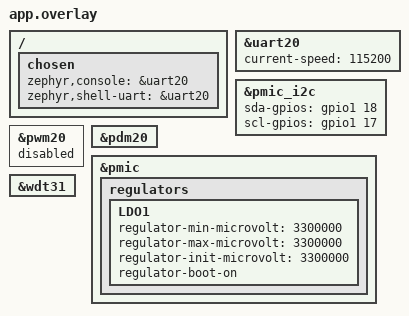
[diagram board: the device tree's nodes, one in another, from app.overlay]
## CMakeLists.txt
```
cmake_minimum_required(VERSION 3.20.0)

# SDK-specific devicetree fixups are applied on top of the auto-included
# app.overlay. They must be selected before find_package(Zephyr), because that
# call preprocesses the devicetree. The NCS and upstream board definitions do
# not expose the same nodes, so applying both overlays is not portable.
#
# A plain set() is correct and does not hide a caller's overlay: Zephyr reads
# this with zephyr_get(EXTRA_DTC_OVERLAY_FILE SYSBUILD LOCAL MERGE REVERSE),
# which merges every scope (sysbuild, CMake cache, environment, and this local
# variable) instead of letting the highest-precedence one win. A deployment
# overlay passed as -DEXTRA_DTC_OVERLAY_FILE=... therefore lands in the DTS list
# alongside the fixup below, with the fixup applied first.
get_filename_component(hive_zephyr_parent "$ENV{ZEPHYR_BASE}" DIRECTORY)
if(DEFINED NCS_DIR OR DEFINED ENV{NCS_DIR} OR
   EXISTS "${hive_zephyr_parent}/nrf/CMakeLists.txt")
  set(hive_sdk_overlay "ncs_fixups.overlay")
else()
  set(hive_sdk_overlay "upstream_fixups.overlay")
endif()
set(EXTRA_DTC_OVERLAY_FILE "${CMAKE_CURRENT_SOURCE_DIR}/${hive_sdk_overlay}")

find_package(Zephyr REQUIRED HINTS $ENV{ZEPHYR_BASE})
project(hiveinside_nrf54lm20a)

target_sources(app PRIVATE
  src/main.c
  src/fft.c
  src/hive_i2c.c
  src/power.c
  src/sht40.c
  src/watchdog.c
  src/accel.c
  src/mic.c
  src/battery.c
  src/beacon.c
  src/link.c
  src/ota.c
  src/audio.c
  # Temporary measurement module (issue #71 phase 0e). Compiles to nothing
  # unless ENABLE_THROUGHPUT_SPIKE is set — see throughput-spike.conf.
  src/throughput.c
)

# ── Version-stamped OTA payload ────────────────────────────────────────────
#
# Zephyr always names the signed application `zephyr.signed.bin`, so every build
# configuration produces a file that is indistinguishable from the others the
# moment it leaves its build directory. That is a real hazard here rather than a
# cosmetic one: the bring-up image and the low-power deployment image
# (docs/low-power.md) are both valid OTA payloads, and pushing the wrong one to
# a sealed hive fails silently — the node boots, advertises, and simply behaves
# like the other build. Copy the signed image next to itself under a name that
# carries the firmware version and the variant.

# The same MAJOR/MINOR/PATCH numbers beacon.c advertises, not the derived
# HIVEINSIDE_FW_VERSION string. Those bytes are what the backend sees, so an
# artifact named v0.4.3 is only honest if it advertises 0.4.3. sysbuild.cmake
# reads them the same way to stamp the signed image header.
include(${CMAKE_CURRENT_SOURCE_DIR}/cmake/hive_version.cmake)
hive_read_identity(${CMAKE_CURRENT_SOURCE_DIR}/src/hive_config.h
  hive_fw_version hive_board)
set_property(DIRECTORY APPEND PROPERTY CMAKE_CONFIGURE_DEPENDS
  ${CMAKE_CURRENT_SOURCE_DIR}/src/hive_config.h)

# CONFIG_SERIAL is the honest discriminator. It is exactly what low-power.conf
# turns off, and it describes what the image *is* rather than how the build was
# requested, so a deployment image cannot end up carrying the bring-up name
# because a flag was passed in an unexpected way.
if(CONFIG_SERIAL)
  set(hive_image_variant "bringup")
else()
  set(hive_image_variant "lowpower")
endif()
# A build that changes the firmware through compiler macros is not the image
# its CONFIG_SERIAL alone suggests. The throughput spike gets a name of its own;
# any other macro override is marked as custom, so neither can be mistaken for
# a release payload once it leaves its build directory. release.yml also
# refuses the spike outright.
if(CONFIG_COMPILER_OPT MATCHES "ENABLE_THROUGHPUT_SPIKE=1")
  set(hive_image_variant "spike")
elseif(NOT "${CONFIG_COMPILER_OPT}" STREQUAL "")
  string(APPEND hive_image_variant "-custom")
endif()

if(NOT hive_fw_version OR NOT hive_board)
  message(WARNING
    "HiveInside: could not read HIVEINSIDE_FW_VERSION/HIVEINSIDE_BOARD from "
    "src/hive_config.h; skipping the version-stamped OTA payload.")
elseif(CONFIG_BOOTLOADER_MCUBOOT AND TARGET zephyr_final)
  set(hive_payload_name
    "hiveinside-${hive_board}-v${hive_fw_version}-${hive_image_variant}.signed.bin")

  add_custom_target(hiveinside_ota_payload ALL
    COMMAND ${CMAKE_COMMAND}
      -DHIVE_SRC=${PROJECT_BINARY_DIR}/zephyr/zephyr.signed.bin
      -DHIVE_DST=${PROJECT_BINARY_DIR}/zephyr/${hive_payload_name}
      -P ${CMAKE_CURRENT_SOURCE_DIR}/cmake/stamp_ota_payload.cmake
    BYPRODUCTS ${PROJECT_BINARY_DIR}/zephyr/${hive_payload_name}
    COMMENT "Stamping OTA payload ${hive_payload_name}"
    VERBATIM
  )

  # Depend on the final image target rather than adding another POST_BUILD
  # command of our own. Signing is itself a POST_BUILD step of zephyr_final —
  # NCS appends it to Zephyr's `extra_post_build_commands` — and a dependent
  # target is guaranteed to run after all of them, whatever order the module
  # hooks happened to be registered in.
  add_dependencies(hiveinside_ota_payload zephyr_final)

  message(STATUS "HiveInside OTA payload: ${hive_payload_name}")
endif()
```

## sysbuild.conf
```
# sysbuild.conf — multi-image (sysbuild) configuration for a `west build`.
#
# PlatformIO's Seeed Zephyr builder builds the application image only, linked
# for MCUboot slot0 via CONFIG_BOOTLOADER_MCUBOOT in prj.conf; the MCUboot
# bootloader is provisioned once (this sysbuild build, or Seeed's prebuilt
# bootloader). A `west build` with sysbuild picks up this file and additionally
# builds MCUboot, producing a complete, OTA-capable set (bootloader + signed
# app in slot0). The board DTS supplies the mcuboot/slot0/slot1/storage RRAM
# partitions, so no partition manager / pm_static file is required.
#
#   west build -b xiao_nrf54lm20a/nrf54lm20a/cpuapp firmware-nrf54lm20a
#
SB_CONFIG_BOOTLOADER_MCUBOOT=y
```

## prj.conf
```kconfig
# HiveInside nRF54LM20A — sensor readout firmware (target 1).
#
# Zephyr picks this up automatically for both build configurations; the
# low-power deployment image layers low-power.conf on top of it through
# EXTRA_CONF_FILE. See docs/vscode-build.md.

# ── Peripherals ──
CONFIG_GPIO=y
CONFIG_I2C=y

# nPM1300 PMIC: fuel-gauge voltage via the sensor API (battery.c) and LDO1
# raised to 3.3 V for the IMU/mic rail (power.c + app.overlay). Both degrade
# gracefully if the devicetree carries no nPM1300 nodes.
CONFIG_SENSOR=y
CONFIG_REGULATOR=y
# nPM1300 is an MFD parent; without this its charger/regulator children compile
# out even though their devicetree nodes are present.
CONFIG_MFD=y

# The board devicetree binds the on-board LSM6DS3TR-C to Zephyr's LSM6DSL
# sensor driver; accel.c owns the chip through raw I²C register access instead,
# so keep the driver from also initialising and configuring it.
CONFIG_LSM6DSL=n

# On-board PDM microphone through the dmic API (mic.c). Compiles to a stub when
# no nordic,nrf-pdm node is enabled in the devicetree.
CONFIG_AUDIO=y
CONFIG_AUDIO_DMIC=y

# ── Float math + float printf ──
# mic.c uses sqrtf()/log10f(); the readout prints floats, which needs the
# cbprintf floating-point formatter.
CONFIG_FPU=y
CONFIG_CBPRINTF_FP_SUPPORT=y

# ── Console over the on-board debugger's USB-CDC bridge (115200) ──
#
# The XIAO nRF54LM20A Sense carries an on-board SAMD11 CMSIS-DAP debugger that
# owns the USB-C port. Besides SWD flashing it bridges the SoC's uart20 (P1.11
# TX / P1.10 RX — internal pins, *not* on the XIAO header) to a USB CDC ACM port
# on the host (/dev/ttyACM0). The board definition already selects
# `zephyr,console = &uart20`, so console output rides that bridge to the PC —
# the nRF54's own USBHS is not used (the SAMD11 owns the port), so no native USB
# device stack is enabled here.
#
# Keep the console a plain polled UART: unlike a USB-CDC console it never blocks
# waiting for a host DTR, so the firmware boots and samples whether or not a
# monitor is open.
CONFIG_SERIAL=y
CONFIG_CONSOLE=y
CONFIG_UART_CONSOLE=y
CONFIG_PRINTK=y

# The application uses only printk(), not Zephyr's LOG_* API. Keep the log
# subsystem disabled so printk() stays a direct, polled UART write and no
# separate log-processing thread is started.
CONFIG_LOG=n

# ── Watchdog ──
# Unattended in-hive operation: a hang inside a sensor driver would otherwise
# leave the node advertising a stale measurement forever. src/watchdog.c arms
# wdt31 (enabled in app.overlay) and main.c feeds it, including through the long
# idle between cycles. See src/hive_config.h for the timeout.
CONFIG_WATCHDOG=y

# Tickless idle is the Zephyr default; pin it so the assumption is explicit.
# Without it the CPU would wake on every system tick throughout the five-minute
# interval, which would dominate every other saving described in
# docs/low-power.md.
CONFIG_TICKLESS_KERNEL=y

# ── HiveHub-compatible connectable BLE measurement beacon + OTA ──
# The controller repeats the last 29-byte reading without waking the CPU.
CONFIG_BT=y
CONFIG_BT_BROADCASTER=y
CONFIG_BT_PERIPHERAL=y
CONFIG_BT_DEVICE_NAME="HiveInside"
# beacon.c rewrites the name at boot to "HiveInside-XXXX" (the last two bytes of
# the identity address) so several nodes in one yard can be told apart, and the
# GAP Device Name characteristic has to follow the scan response — which needs a
# writable name buffer. The literal above stays as the fallback the node boots
# with and the prefix the suffix is appended to.
CONFIG_BT_DEVICE_NAME_DYNAMIC=y
# 15 characters plus the terminator. The default (28) would only reserve RAM for
# a name this firmware can never produce.
CONFIG_BT_DEVICE_NAME_MAX=15
# Keep legacy advertising (ADV_IND). Only the legacy PDU may carry both the
# measurement (primary packet) and the name (scan response) at once; extended
# advertising forbids that pair, so pin it off to avoid a rejected beacon.
CONFIG_BT_EXT_ADV=n
CONFIG_BT_MAX_CONN=1
CONFIG_BT_GATT_DYNAMIC_DB=n

# beacon.c restarts advertising from the system workqueue after a disconnect
# (see the comment on adv_restart_work there), and ota.c drives the connection
# teardown and reboot from it too. bt_le_adv_start() plus the synchronous HCI
# command it blocks on is deeper than the 1024-byte Zephyr default was chosen
# for; 1 KiB more RAM is the cheapest possible way to not have to reason about
# that margin.
CONFIG_SYSTEM_WORKQUEUE_STACK_SIZE=2048

# HiveHub requests MTU 247 and sends up to 244 payload bytes per DATA write.
CONFIG_BT_L2CAP_TX_MTU=247
CONFIG_BT_BUF_ACL_RX_SIZE=251
CONFIG_BT_BUF_ACL_TX_SIZE=251
# Six 251-byte TX buffers let notifications fill a connection event; the five
# extra buffers cost roughly CONFIG_BT_BUF_ACL_TX_SIZE bytes each in RAM.
CONFIG_BT_BUF_ACL_TX_COUNT=6
# Audio explicitly negotiates maximum data length and 2M PHY: the measured link
# loses roughly two thirds of its throughput if left at the central's defaults.
CONFIG_BT_USER_DATA_LEN_UPDATE=y
CONFIG_BT_USER_PHY_UPDATE=y

# START authentication uses HMAC-SHA256. Keeping this in PSA rather than a
# local primitive gives the provisioned key one audited crypto boundary. The
# repository pins upstream Zephyr, where PSA_CRYPTO is the provider switch;
# NRF_SECURITY is an NCS-only symbol and makes Kconfig warnings fatal here.
CONFIG_PSA_CRYPTO=y
CONFIG_PSA_WANT_ALG_HMAC=y
CONFIG_PSA_WANT_ALG_SHA_256=y
CONFIG_PSA_WANT_KEY_TYPE_HMAC=y

# MCUboot test swap and direct streaming into the secondary fixed partition.
CONFIG_BOOTLOADER_MCUBOOT=y
CONFIG_MCUBOOT_IMG_MANAGER=y
CONFIG_IMG_MANAGER=y
CONFIG_STREAM_FLASH=y
CONFIG_FLASH=y
CONFIG_FLASH_MAP=y
CONFIG_FLASH_PAGE_LAYOUT=y
CONFIG_CRC=y
CONFIG_REBOOT=y

# ── Writing RRAM while the radio is up (this is what makes OTA work) ───────
#
# An OTA writes the secondary slot from inside a GATT write callback, i.e. with
# a live BLE connection. On this SoC that is not a plain memory write: upstream
# Zephyr's link layer (CONFIG_BT_LL_SW_SPLIT) makes
# SOC_FLASH_NRF_RADIO_SYNC_TICKER the default for the RRAM driver, so every
# flash_write() issued once the controller is running is executed inside a
# ticker-scheduled radio timeslot — see drivers/flash/soc_flash_nrf_rram.c and
# subsys/bluetooth/controller/flash/soc_flash_nrf_ticker.c. Two properties of
# that path decide whether an OTA can complete at all, and both are governed by
# the setting below:
#
#   * The timeslot length comes from CONFIG_NRF_RRAM_WRITE_BUFFER_SIZE
#     (FLASH_SLOT_WRITE is 500 us at the default of 1, 8000 us at 32), and
#     nrf_flash_sync_set_context() then derives the flash ticker's period as
#     `slot - FLASH_SYNC_SWITCHING_TIME`, where the switching time is a fixed
#     1700 us. At the default of 1 that subtraction is 500 - 1700 on an
#     unsigned value: it wraps, and the flash ticker is left with a nonsense
#     period instead of a usable one.
#   * nrf_flash_sync_check_time_limit() returns true unconditionally on
#     nRF54Lx — RRAM writes are not constant-time, so the driver deliberately
#     does no more than one iteration per timeslot. One timeslot therefore
#     moves at most CONFIG_NRF_RRAM_WRITE_BUFFER_SIZE 128-bit lines, i.e. 16
#     bytes at the default of 1, and a single 512-byte flush would need 32
#     consecutive timeslots on that broken schedule.
#
# The visible symptom is precise and worth recording, because it looks nothing
# like a flash problem from the relay's side: BEGIN succeeds (it touches no
# flash beyond flash_img_init()), the first two 244-byte DATA chunks succeed
# (they only fill stream_flash's buffer), and the *third* fails — that is the
# write that first fills the 512-byte buffer and so triggers the first real
# flash_write(). The device answers ATT "unlikely error", reports OTA_ERR_WRITE
# (state 0x12) with received=488, and the radio events the flash ticker aborted
# in the meantime take the link down with a supervision timeout (HCI 0x08).
#
# 32 is the maximum the driver allows and fixes both halves: the period becomes
# 8000 - 1700 = 6300 us, and one timeslot moves a full 512 bytes.
CONFIG_NRF_RRAM_WRITE_BUFFER_SIZE=32

# Pin the image writer's buffer to exactly the 512 bytes one timeslot can now
# carry, so each flash_img_buffered_write() flush is a single flash_write() that
# finishes in a single timeslot. This is also Zephyr's current default; it is
# stated here because it is no longer a free choice — a larger buffer would
# silently put the transfer back on the multi-timeslot path described above.
CONFIG_IMG_BLOCK_BUF_SIZE=512

# The microphone capture and float formatting run on the main thread. Reserve
# headroom for the deepest driver/printf call chain so a stack overrun cannot
# turn into a hard-fault/reset loop.
CONFIG_MAIN_STACK_SIZE=8192
```

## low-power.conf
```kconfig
# Deployment profile: remove the always-on diagnostic UART and its formatting
# support. Sensor values continue to be published over BLE and OTA remains
# available. Apply together with low-power.overlay; see docs/low-power.md.
#
# This file holds only the deltas from prj.conf. Everything the application
# needs at runtime — BLE, MCUboot/OTA, the sensor stack — stays as prj.conf
# defines it. CONFIG_LOG is already n in prj.conf and is not repeated here.
#
# Note the trade-off: with the console and printk() gone, this image reports
# nothing on failure. A wedged driver or a persistent LDO1 error is invisible
# except as stale values in the beacon. The watchdog still recovers a hang —
# it is enabled in prj.conf, so it applies here too — but diagnosing why needs
# the normal build.
CONFIG_SERIAL=n
CONFIG_CONSOLE=n
CONFIG_UART_CONSOLE=n
CONFIG_PRINTK=n

# CONFIG_BOOT_BANNER is `default y` and *selects* PRINTK, which would drag
# printk() back in and make the CONFIG_PRINTK=n above a no-op — Kconfig reports
# this as "PRINTK was assigned the value 'n' but got the value 'y'". A boot
# banner on an image with no console is pointless anyway.
CONFIG_BOOT_BANNER=n

# printk() was the only float-formatting user; with it gone the cbprintf
# floating-point formatter is dead code. The float math in mic.c/fft.c is
# unaffected — that is CONFIG_FPU, which stays on.
CONFIG_CBPRINTF_FP_SUPPORT=n

# Deliberately NOT set here: CONFIG_PM_DEVICE. Without CONFIG_PM (system power
# management) or CONFIG_PM_DEVICE_RUNTIME, nothing ever runs a device's suspend
# action, so it costs flash and alters driver init paths while saving no power.
# Enabling Zephyr device PM is a measured change, not a free one — see the
# "Device power management" section of docs/low-power.md before adding it.
```

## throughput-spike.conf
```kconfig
# TEMPORARY measurement profile: BLE notification throughput (issue #71, phase 0e).
#
# Layer this on top of prj.conf the same way low-power.conf is layered — as an
# EXTRA Kconfig fragment, never a base one (see docs/vscode-build.md for why
# that distinction matters). On the command line:
#
#   west build --sysbuild -b xiao_nrf54lm20a/nrf54lm20a/cpuapp -d spike \
#       firmware-nrf54lm20a -- -DEXTRA_CONF_FILE=throughput-spike.conf
#
# This is a bench image. It keeps the console (it is layered on prj.conf, not on
# low-power.conf) because the measurement is read from the serial log as well as
# over GATT, and it must never be uploaded as a release: the extra GATT service
# lets anything in radio range make the node transmit continuously.
#
# See docs/ble-throughput-spike.md for how to run it and what the numbers mean.

# Compile src/throughput.c in. The application's switches are plain C macros in
# src/hive_config.h (deliberately overridable "from the build"), so this is how
# a Kconfig fragment reaches one.
CONFIG_COMPILER_OPT="-DENABLE_THROUGHPUT_SPIKE=1"

# The spike advertises as "HiveInside-TP-XXXX" (src/hive_config.h), so a scan
# tells it apart from a deployment image; that needs three more name bytes.
CONFIG_BT_DEVICE_NAME_MAX=18

# Link-parameter visibility and control. Both symbols do double duty: they
# enable the bt_conn_le_*_update() calls the spike makes, and they are what
# compile the matching .le_phy_updated / .le_data_len_updated callbacks into
# struct bt_conn_cb, which is where the answer to "are we really running 2M PHY
# and 251-byte PDUs?" actually comes from.
CONFIG_BT_USER_DATA_LEN_UPDATE=y
CONFIG_BT_USER_PHY_UPDATE=y

# The knob most likely to move the result. Each controller TX buffer is one
# notification that can be queued into a connection event, and throughput.c
# takes its credit count straight from this symbol — so re-running the
# measurement at 3, 6 (the prj.conf value) and 12 sweeps notifications-per-event
# without touching a line of code.
#
# Raising it costs RAM: roughly CONFIG_BT_BUF_ACL_TX_SIZE (251) bytes plus
# overhead per buffer. Check the build's RAM report when sweeping upward.
CONFIG_BT_BUF_ACL_TX_COUNT=6
```

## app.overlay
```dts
/*
 * app.overlay — HiveInside adjustments to the XIAO nRF54LM20A board DT.
 *
 * Zephyr includes this automatically for every build configuration; the
 * low-power deployment image layers low-power.overlay on top of it through
 * EXTRA_DTC_OVERLAY_FILE. See docs/vscode-build.md.
 *
 * Everything else the firmware needs is already enabled by the upstream board
 * definition: i2c22 (the XIAO header bus, external SHT40), i2c30 (internal bus
 * with the LSM6DS3TR-C at 0x6a) and the nPM1300 charger/regulator nodes.
 */
#include <zephyr/dt-bindings/gpio/gpio.h>

/ {
	chosen {
		/* Console routing.
		 *
		 * uart20 (P1.11 TX / P1.10 RX) is wired to the on-board SAMD11
		 * CMSIS-DAP debugger, which bridges it to a USB CDC ACM port
		 * (/dev/ttyACM0) over the same USB-C cable used for flashing.
		 * The board definition already chooses uart20; re-assert it here
		 * so the application console does not silently move if a future
		 * board-definition bump changes the default. The XIAO header
		 * UART is uart21 on D6/D7 — deliberately NOT the console. */
		zephyr,console = &uart20;
		zephyr,shell-uart = &uart20;
	};
};

/* Belt-and-suspenders: the board definition already enables uart20 at
 * 115200 8N1; keep it explicit next to the console choice above. */
&uart20 {
	status = "okay";
	current-speed = <115200>;
};

/* nPM1300 PMIC bit-banged I2C — pin correction.
 *
 * The board DTS routes the PMIC's bit-banged I2C to P1.15 (SDA) / P1.16 (SCL),
 * but the actual XIAO nRF54LM20A Sense hardware wires the nPM1300 to
 * P1.18 (SDA) / P1.17 (SCL). Without this override the firmware talks to the
 * wrong pins, the nPM1300 is unreachable, and LDO1 stays at its 1.8 V default —
 * enough for the LSM6DS3TR-C IMU (on the separate i2c30 bus) but too low for
 * the MSM261DGT006 microphone, whose PDM capture then returns no data. Matches
 * Seeed's own on-board-sensor reference overlay. */
&pmic_i2c {
	sda-gpios = <&gpio1 18 GPIO_ACTIVE_HIGH>;
	scl-gpios = <&gpio1 17 GPIO_ACTIVE_HIGH>;
	status = "okay";
};

/* Free the peripheral slot the PDM shares with PWM.
 *
 * On the nRF54L the "20" peripheral group multiplexes pdm20 and pwm20 onto the
 * same underlying block/pins, so only one can run at a time. The board enables
 * pwm20 by default, which leaves pdm20 able to be configured and "started" yet
 * never actually sampling — dmic_read() then times out with zero DMA blocks
 * ("read stopped after 0 frames"). Disabling pwm20 releases the slot to the
 * microphone. (Per Seeed's working on-board-mic overlay.) */
&pwm20 {
	status = "disabled";
};

/* On-board PDM microphone (MSM261DGT006). The board definition provides
 * pinctrl (P1.13 CLK / P1.14 DIN) and clock-source but leaves the controller
 * disabled. */
&pdm20 {
	status = "okay";
};

/* The Sense module powers the PDM microphone (and, on this board, the IMU) from
 * the nPM1300's LDO1. The board default is 1.8 V; the microphone needs 3.3 V.
 * Keep the rail at 3.3 V and enable it at boot so it is already correct before
 * any code runs; src/power.c then re-asserts 3.3 V and waits for the parts to
 * settle. regulator-init-microvolt makes the rail correct even if power.c is
 * ever compiled out. This only takes effect once &pmic_i2c above can actually
 * reach the nPM1300. */
&pmic {
	regulators {
		LDO1 {
			regulator-min-microvolt = <3300000>;
			regulator-max-microvolt = <3300000>;
			regulator-init-microvolt = <3300000>;
			regulator-boot-on;
		};
	};
};

/* Watchdog for unattended operation (src/watchdog.c).
 *
 * Both nRF54LM20A watchdog instances ship disabled in the SoC devicetree.
 * wdt31 is chosen over wdt30 because wdt30 is compiled out of the SoC
 * devicetree entirely under a non-secure address map, so wdt31 is the instance
 * that exists in every build variant. */
&wdt31 {
	status = "okay";
};
```

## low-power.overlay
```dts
/* Deployment profile — apply together with low-power.conf; see
 * docs/low-power.md.
 *
 * uart20 is useful during bring-up but is unnecessary in a sealed beacon.
 * Disabling the node keeps the peripheral unconfigured and leaves its pins in
 * the reset (disconnected) state. app.overlay still names uart20 as
 * zephyr,console, but with CONFIG_UART_CONSOLE=n nothing resolves that chosen
 * node, so a disabled console node is harmless here. */
&uart20 {
	status = "disabled";
};

/* The fresh-measurement blink is diagnostic only, so drop it from a deployment
 * image. This is a behaviour change, not a power optimisation: the LED is
 * active-low and main.c already drives the pin inactive, so a disabled node
 * saves only the 100 ms blink itself — about 0.03 % duty at the default
 * five-minute interval. main.c compiles the blink out via the led0 alias
 * status check, so nothing else has to change. */
&blue_led {
	status = "disabled";
};

/* Do not hold the IMU/microphone island powered from reset.
 *
 * `power_en` (P1.12) carries `regulator-boot-on` in the board devicetree and
 * app.overlay adds the same property to LDO1, so both rails come up before
 * main() runs and stay up until src/power.c first switches them. src/power.c
 * releases the regulator core's init reference so the runtime gating works
 * either way, but leaving boot-on in place for a deployment image means the
 * sensor island is powered for the whole of MCUboot plus application init, and
 * that power_init() has to disable and re-enable each rail to normalise the
 * reference count. Removing the property here avoids both.
 *
 * Only the deployment profile does this. The bring-up build keeps boot-on so
 * the rail is already at 3.3 V if power.c is ever compiled out or fails to
 * reach the nPM1300. */
&power_en {
	/delete-property/ regulator-boot-on;
};

&pmic {
	regulators {
		LDO1 {
			/delete-property/ regulator-boot-on;
		};
	};
};

/* Two nodes Seeed's low-power guide also lists are deliberately NOT touched
 * here, because on the board devicetree this project builds against they would
 * be a no-op and a build failure respectively:
 *
 * - The external 8 MB SPI NOR (`py25q64`) already ships `status = "disabled"`,
 *   so the driver never probes it and there is nothing to switch off. Seeed's
 *   guide goes the other way and *enables* the node, because reaching the
 *   part's ~1 uA deep-power-down state requires a driver to issue the DPD
 *   command (`has-dpd` is present in the node, and Zephyr's spi_nor driver
 *   exposes this as CONFIG_SPI_NOR_IDLE_IN_DPD). That is a real saving over an
 *   unprobed part left in standby, but it is a measured change with a driver
 *   and SPI pin states attached, not an overlay line — see docs/low-power.md.
 *
 * - `pmic_leds` does not exist. The nPM1300 node here has `charger` and
 *   `regulators` children only; the `nordic,npm1300-led` child and its label
 *   were added in a later Seeed board revision than either tree this firmware
 *   builds against. Referencing a missing label is a hard devicetree error
 *   ("label or path, 'pmic_leds', not found"), so the line would break the
 *   deployment build rather than save anything. With no LED child node, no LED
 *   driver is built and the engine is left in its reset state anyway. */
```

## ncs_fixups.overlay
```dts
/*
 * nRF Connect SDK board-tree fixups — applied by the top-level CMakeLists.txt
 * (see EXTRA_DTC_OVERLAY_FILE there). Kept separate from app.overlay because
 * these differences only bite an NCS workspace, whose sdk-zephyr board tree
 * disagrees with upstream Zephyr's.
 *
 * NCS's nRF54LM20A SoC leaves the USBHS wrapper node (nordic,nrf-usbhs-wrapper)
 * enabled by default. With CONFIG_REGULATOR on — which this firmware needs for
 * the nPM1300 fuel gauge and LDO control — the nrf_usbhs_wrapper driver builds
 * itself in (it is `default y` on that node + REGULATOR) and does
 * DEVICE_DT_GET() on the VREGUSB regulator device that this non-USB
 * configuration never instantiates, failing the build with
 * "__device_dts_ord_N undeclared" in nrf_usbhs_wrapper.c.
 *
 * This firmware does not use the nRF54's native USB: the on-board SAMD11
 * CMSIS-DAP debugger owns the USB-C port and bridges uart20 to the host. So
 * disable the wrapper node; that clears DT_HAS_NORDIC_NRF_USBHS_WRAPPER_ENABLED
 * and the driver is no longer built.
 */
&usbhs_wrapper {
	status = "disabled";
};
```

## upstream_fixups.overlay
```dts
/*
 * Fixups for the upstream Zephyr XIAO nRF54LM20A board definition.
 *
 * The board enables the physical crystals and the parent clock controller but
 * leaves its child clock devices disabled. Bluetooth requires the LFCLK and XO
 * devices, while PDM can request XO24M. Name the children relative to &clock
 * instead of referring to their optional labels: some upstream revisions omit
 * those labels even though the child node names are stable.
 */
&clock {
	xo {
		compatible = "nordic,nrf-clock-xo";
		clock-frequency = <DT_FREQ_M(32)>;
		#clock-cells = <0>;
		status = "okay";
	};

	lfclk {
		compatible = "nordic,nrf-clock-lfclk";
		status = "okay";
	};

	xo24m {
		compatible = "nordic,nrf-clock-xo24m";
		clock-frequency = <DT_FREQ_M(24)>;
		#clock-cells = <0>;
		status = "okay";
	};
};
```

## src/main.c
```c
/*
 * main.c — HiveInside XIAO nRF54LM20A Sense sensor readout (target 1).
 *
 * Bring up the sensor power rail, then every MEASURE_INTERVAL_MS read all four
 * sensors — SHT40 climate, LSM6DS3TR-C acceleration, PDM microphone level and
 * nPM1300 battery — and print the result to the USB serial console.
 *
 * "USB serial console": the on-board SAMD11 CMSIS-DAP debugger bridges the
 * SoC's uart20 to a USB CDC ACM port (/dev/ttyACM0) over the same USB-C cable
 * used for flashing, so printk() output appears on the host with no second
 * adapter. See docs/flashing.md. The console is a plain polled UART, so the
 * firmware boots and keeps sampling whether or not a terminal is attached.
 *
 * Alongside the plain readings it runs the same vibration and acoustic FFT band
 * analysis as HiveScale, prints those bands, and broadcasts the reduced
 * measurement in HiveHub's BLE manufacturer-data format.
 */
#include "accel.h"
#include "battery.h"
#include "beacon.h"
#include "hive_config.h"
#include "measurement.h"
#include "audio.h"
#include "link.h"
#include "mic.h"
#include "ota.h"
#include "power.h"
#include "sht40.h"
#include "watchdog.h"

#include <zephyr/kernel.h>
#include <zephyr/drivers/gpio.h>
#include <zephyr/sys/printk.h>
#include <zephyr/sys/reboot.h>
#include <zephyr/dfu/mcuboot.h>

#define MEASUREMENT_LED_NODE DT_ALIAS(led0)

#if DT_NODE_HAS_STATUS(MEASUREMENT_LED_NODE, okay)
static const struct gpio_dt_spec measurement_led =
	GPIO_DT_SPEC_GET(MEASUREMENT_LED_NODE, gpios);
static bool measurement_led_ready;

static void measurement_led_init(void)
{
	if (!gpio_is_ready_dt(&measurement_led)) {
		printk("[LED] built-in LED controller is not ready\n");
		return;
	}
	int err = gpio_pin_configure_dt(&measurement_led, GPIO_OUTPUT_INACTIVE);

	if (err != 0) {
		printk("[LED] built-in LED setup failed (%d)\n", err);
		return;
	}
	measurement_led_ready = true;
}

static void measurement_led_blink(void)
{
	if (!measurement_led_ready) {
		return;
	}
	(void)gpio_pin_set_dt(&measurement_led, 1);
	k_msleep(MEASUREMENT_LED_BLINK_MS);
	(void)gpio_pin_set_dt(&measurement_led, 0);
}
#else
static void measurement_led_init(void)
{
	printk("[LED] no led0 devicetree alias; measurement blink disabled\n");
}

static void measurement_led_blink(void)
{
}
#endif

/* Wait out the interval between sensor cycles in watchdog-sized slices.
 *
 * A single k_msleep(MEASURE_INTERVAL_MS) would force the watchdog timeout to
 * exceed the whole sampling period, which would let a driver hang go unnoticed
 * for five minutes. Sleeping in slices keeps the timeout sized against one
 * blocking call instead. The slice boundary is the only thing that changes:
 * the CPU is still idle for the entire interval apart from the feed itself. */
static void idle_between_cycles(void)
{
	uint32_t remaining = MEASURE_INTERVAL_MS;

	while (remaining > 0U) {
		uint32_t slice = MIN(remaining, (uint32_t)HIVE_WDT_FEED_INTERVAL_MS);

		k_msleep((int32_t)slice);
		remaining -= slice;
		hive_watchdog_feed();
	}
}

static void print_readout(const struct measurement *m)
{
	printk("---- HiveInside readout ----\n");

	if (m->sht_ok) {
		printk("  climate : %.2f C   %.1f %%RH\n", (double)m->temp_c,
		       (double)m->humidity_pct);
	} else {
		printk("  climate : n/a\n");
	}

	if (m->accel_ok) {
		printk("  accel   : x=%.1f y=%.1f z=%.1f mg  |a|=%.1f mg\n",
		       (double)m->accel_x_mg, (double)m->accel_y_mg,
		       (double)m->accel_z_mg, (double)m->accel_mag_mg);
		printk("  accel AC: rms=%.1f peak=%.1f mg  (%u@%uHz)\n",
		       (double)m->accel_rms_mg, (double)m->accel_peak_mg,
		       (unsigned)m->accel_sample_count,
		       (unsigned)m->accel_sample_rate_hz);
		printk("  vib FFT : swarm=%.2f fan=%.2f act=%.2f mg\n",
		       (double)m->accel_band_swarm_mg,
		       (double)m->accel_band_fanning_mg,
		       (double)m->accel_band_activity_mg);
	} else {
		printk("  accel   : n/a\n");
	}

	if (m->mic_ok) {
		printk("  sound   : rms=%.1f dBFS  peak=%.1f dBFS  (%u frames)\n",
		       (double)m->mic_rms_dbfs, (double)m->mic_peak_dbfs,
		       (unsigned)m->mic_frames);
		printk("  ac FFT  : sub=%.1f hum=%.1f pipe=%.1f stress=%.1f hi=%.1f dBFS\n",
		       (double)m->mic_band_sub_bass_dbfs,
		       (double)m->mic_band_hum_dbfs,
		       (double)m->mic_band_piping_dbfs,
		       (double)m->mic_band_stress_dbfs,
		       (double)m->mic_band_high_dbfs);
	} else {
		printk("  sound   : n/a\n");
	}

	if (m->battery_ok) {
		printk("  battery : %.3f V  ~%u%%\n", (double)m->battery_v,
		       (unsigned)m->battery_pct);
	} else {
		printk("  battery : n/a\n");
	}

	printk("----------------------------\n");
}

/* Rollback safety net for MCUboot test images. A healthy image confirms within
 * the first sensor cycle (seconds after boot); if confirmation has not happened
 * within this window the image is deemed unhealthy — radio never came up, the
 * main loop is wedged in a sensor driver, or the trailer write keeps failing —
 * and we reboot so MCUboot reverts to the previous image. The window is a
 * generous multiple of a normal first cycle yet well under MEASURE_INTERVAL_MS,
 * so recovery does not have to wait a full sampling period. */
#define OTA_CONFIRM_DEADLINE_MS 120000U

static void ota_confirm_deadline_expired(struct k_timer *timer)
{
	ARG_UNUSED(timer);
	/* Only ever armed while running an unconfirmed test image with a staged
	 * rollback target, so a reset here reverts to the previous known image. */
	printk("[OTA] health deadline expired without confirmation; rebooting for rollback\n");
	sys_reboot(SYS_REBOOT_COLD);
}

K_TIMER_DEFINE(ota_confirm_deadline, ota_confirm_deadline_expired, NULL);

int main(void)
{
	bool confirmation_pending;
	bool confirmation_attempted = false;
	int beacon_err;

	printk("\n[HiveInside] %s fw %s | USB + HiveHub BLE beacon\n",
	       HIVEINSIDE_BOARD, HIVEINSIDE_FW_VERSION);

	/* Both recovery mechanisms are armed before any initializer that could
	 * hang. A regulator or Bluetooth init that never returns would otherwise
	 * leave the node dark until someone power-cycles it, and an unconfirmed
	 * test image could not reach the reset MCUboot needs to revert it. The
	 * watchdog's timeout is far longer than the whole init sequence. */
	hive_watchdog_init();
	confirmation_pending = !boot_is_img_confirmed();
	/* Arm the rollback deadline only for a genuine test swap (a previous image
	 * is staged for revert). A directly SWD-flashed image reports swap type
	 * NONE and has no rollback target, so it is never armed and cannot boot
	 * loop; it still self-confirms through the normal path below. */
	if (confirmation_pending && mcuboot_swap_type() == BOOT_SWAP_TYPE_REVERT) {
		k_timer_start(&ota_confirm_deadline, K_MSEC(OTA_CONFIRM_DEADLINE_MS),
			      K_NO_WAIT);
	}

	power_init();
	measurement_led_init();
	beacon_err = beacon_init();
	ota_init();
	audio_init();
	/* power_init() owns the boot-time rail reference; normal users take their
	 * own references below. */
	(void)power_sensor_rail_disable();
	/* Do not confirm a test image merely because main() was reached. Wait until
	 * one complete sensor cycle has run and Bluetooth has successfully published
	 * it; otherwise a regression in either path must remain eligible for MCUboot
	 * rollback on the next reset. An image whose watchdog did not start has
	 * lost the safety net for every later hang, so it is not confirmed either:
	 * reverting to the image that had one is the safer outcome. */
	if (confirmation_pending && beacon_err != 0) {
		printk("[OTA] image left unconfirmed: Bluetooth init failed (%d)\n",
		       beacon_err);
	}
	if (confirmation_pending && !hive_watchdog_active()) {
		printk("[OTA] image left unconfirmed: watchdog did not start\n");
	}

	while (true) {
		hive_watchdog_feed();

		if (link_is_busy()) {
			/* A firmware upload legitimately takes minutes. Polling here
			 * means the main thread is healthy, so keep feeding: the
			 * watchdog must not cut a transfer short. */
			k_msleep(100);
			continue;
		}
		if (!link_measurement_begin()) {
			continue;
		}
		struct measurement m = { 0 };

		/* LDO1 is normally off between cycles. Wake the IMU and microphone
		 * immediately before acquisition, then remove their standby load once
		 * both captures are complete. Climate and battery use other rails. */
		(void)power_sensor_rail_enable();
		sht40_read(&m);
		accel_read(&m);
		mic_read(&m);
		(void)power_sensor_rail_disable();
		link_measurement_end();
		battery_read(&m);

		print_readout(&m);
		if (beacon_publish(&m) == 0) {
			measurement_led_blink();
			if (confirmation_pending && !confirmation_attempted &&
			    hive_watchdog_active() && !link_is_busy()) {
				/* Make at most one trailer-write attempt per boot. A persistent
				 * flash error must not cause periodic writes for the lifetime of
				 * the device; leaving the image unconfirmed preserves rollback. */
				confirmation_attempted = true;
				int confirm_err = boot_write_img_confirmed();

				if (confirm_err == 0) {
					confirmation_pending = false;
					k_timer_stop(&ota_confirm_deadline);
					printk("[OTA] test image confirmed after first complete cycle\n");
				} else {
					printk("[OTA] image confirmation failed (%d); no retry before reset\n",
					       confirm_err);
				}
			}
		}

		idle_between_cycles();
	}

	return 0;
}
```

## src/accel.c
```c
/* accel.c — see accel.h.
 *
 * Raw-register I²C access, so the readout does not depend on which Zephyr
 * driver the board devicetree happens to bind to the on-board IMU. The chip is
 * identified by WHO_AM_I, so either the Sense module's LSM6DS3TR-C or a
 * external LIS3DH breakout works unchanged. Both are sampled at ~400 Hz into
 * the same magnitude/FFT pipeline HiveScale uses, so the band values mean the
 * same thing across the ecosystem.
 *
 * The sensor is powered down between cycles (ODR = 0) — on the Sense module the
 * IMU rail (nPM1300 LDO1) stays up for the mic anyway, so power-down current is
 * the floor either way.
 */
#include "accel.h"

#include "fft.h"
#include "hive_config.h"
#include "hive_i2c.h"

#include <math.h>
#include <zephyr/drivers/i2c.h>
#include <zephyr/kernel.h>
#include <zephyr/sys/printk.h>

#if ENABLE_ACCEL

enum accel_chip {
	CHIP_NONE = 0,
	CHIP_LIS3DH, /* LIS3DH / LIS2DH12 — identical for everything used */
	CHIP_LSM6,   /* LSM6DS3TR-C / LSM6DS3 / LSM6DSL / LSM6DSO */
};

/* ── LIS3DH register map ── */
#define LIS_REG_WHO_AM_I 0x0F /* == 0x33 */
#define LIS_REG_CTRL1    0x20 /* ODR + axis enables */
#define LIS_REG_CTRL4    0x23 /* BDU, full-scale, high-res */
#define LIS_REG_STATUS   0x27 /* ZYXDA = new-data ready */
#define LIS_REG_OUT_X_L  0x28
#define LIS_AUTO_INC     0x80 /* multi-byte read bit */
#define LIS_WHO_AM_I_VAL 0x33
#define LIS_ODR_HZ       400
#define LIS_MG_PER_DIGIT 1.0f /* ±2 g, 12-bit high-resolution */

/* ── LSM6DS3TR-C register map (subset; shared across the LSM6 family) ── */
#define LSM6_REG_WHO_AM_I 0x0F /* 0x69/0x6A/0x6C depending on variant */
#define LSM6_REG_CTRL1_XL 0x10 /* accel ODR + full scale */
#define LSM6_REG_STATUS   0x1E /* bit0 XLDA = accel data ready */
#define LSM6_REG_OUTX_L   0x28 /* auto-increments (IF_INC defaults on) */
#define LSM6_ODR_HZ       416
#define LSM6_CTRL1_416_2G 0x60 /* ODR_XL = 416 Hz, FS = ±2 g */
#define LSM6_MG_PER_LSB   0.061f /* ±2 g sensitivity */

static const struct device *acc_bus;
static uint8_t acc_addr;
static enum accel_chip acc_chip;
static bool probed;

/* FFT scratch — static so a failed cycle can never leak heap. */
static float fft_re[ACCEL_SAMPLE_COUNT];
static float fft_im[ACCEL_SAMPLE_COUNT];

static int rd_regs(uint8_t reg, uint8_t *buf, size_t len)
{
	return i2c_write_read(acc_bus, acc_addr, &reg, 1, buf, len);
}

static int wr_reg(uint8_t reg, uint8_t val)
{
	uint8_t tx[2] = { reg, val };

	return i2c_write(acc_bus, tx, sizeof(tx), acc_addr);
}

static bool probe_addr(const struct device *bus, uint8_t addr,
		       enum accel_chip *chip)
{
	uint8_t reg = LIS_REG_WHO_AM_I; /* same offset on both families */
	uint8_t who = 0;

	if (i2c_write_read(bus, addr, &reg, 1, &who, 1) != 0) {
		return false;
	}
	if (who == LIS_WHO_AM_I_VAL) {
		*chip = CHIP_LIS3DH;
		return true;
	}
	if (who == 0x69 || who == 0x6A || who == 0x6C) {
		*chip = CHIP_LSM6;
		return true;
	}
	return false;
}

static void locate(void)
{
	static const uint8_t addrs[] = { 0x6A, 0x6B, 0x18, 0x19 };
	const struct device *buses[4];
	size_t n = hive_i2c_buses(buses, ARRAY_SIZE(buses));

	for (size_t b = 0; b < n; b++) {
		for (size_t a = 0; a < ARRAY_SIZE(addrs); a++) {
			enum accel_chip chip;

			if (probe_addr(buses[b], addrs[a], &chip)) {
				acc_bus = buses[b];
				acc_addr = addrs[a];
				acc_chip = chip;
				printk("[ACCEL] %s at 0x%02X on %s\n",
				       chip == CHIP_LIS3DH ? "LIS3DH"
							   : "LSM6-class IMU",
				       addrs[a], buses[b]->name);
				return;
			}
		}
	}
	acc_chip = CHIP_NONE;
	printk("[ACCEL] no accelerometer found\n");
}

static void power_down(void)
{
	if (acc_chip == CHIP_LIS3DH) {
		wr_reg(LIS_REG_CTRL1, 0x00);
	} else if (acc_chip == CHIP_LSM6) {
		wr_reg(LSM6_REG_CTRL1_XL, 0x00);
	}
}

/* Configure for the capture; returns the actual sample rate (0 on failure). */
static uint16_t configure(void)
{
	if (acc_chip == CHIP_LIS3DH) {
		/* CTRL1: ODR 400 Hz | XYZ enable. CTRL4: BDU | ±2 g | HR. */
		if (wr_reg(LIS_REG_CTRL1, 0x77) != 0 ||
		    wr_reg(LIS_REG_CTRL4, 0x88) != 0) {
			return 0;
		}
		return LIS_ODR_HZ;
	}
	if (acc_chip == CHIP_LSM6) {
		if (wr_reg(LSM6_REG_CTRL1_XL, LSM6_CTRL1_416_2G) != 0) {
			return 0;
		}
		return LSM6_ODR_HZ;
	}
	return 0;
}

/* Poll data-ready then read one X/Y/Z sample in milli-g. Bounded wait so a
 * wedged bus cannot stall the cycle. */
static bool sample_xyz(uint32_t period_us, float *x_mg, float *y_mg,
		       float *z_mg)
{
	uint8_t status_reg = (acc_chip == CHIP_LIS3DH) ? LIS_REG_STATUS
						       : LSM6_REG_STATUS;
	uint8_t ready_mask = (acc_chip == CHIP_LIS3DH) ? 0x08 : 0x01;
	int64_t deadline = k_uptime_ticks() +
			   k_us_to_ticks_ceil64(period_us * 4 + 2000);
	uint8_t status = 0;

	while (true) {
		if (rd_regs(status_reg, &status, 1) == 0 &&
		    (status & ready_mask)) {
			break;
		}
		if (k_uptime_ticks() > deadline) {
			/* Reading after data-ready timed out returned the previous sample,
			 * making a stuck IMU look like valid zero vibration. Fail this
			 * sample so accel_read() rejects a short capture instead. */
			return false;
		}
		k_usleep(200);
	}

	uint8_t raw[6];
	uint8_t data_reg = (acc_chip == CHIP_LIS3DH)
				   ? (LIS_REG_OUT_X_L | LIS_AUTO_INC)
				   : LSM6_REG_OUTX_L;

	if (rd_regs(data_reg, raw, sizeof(raw)) != 0) {
		return false;
	}

	int16_t xr = (int16_t)(((uint16_t)raw[1] << 8) | raw[0]);
	int16_t yr = (int16_t)(((uint16_t)raw[3] << 8) | raw[2]);
	int16_t zr = (int16_t)(((uint16_t)raw[5] << 8) | raw[4]);

	if (acc_chip == CHIP_LIS3DH) {
		/* 12-bit high-resolution, left-justified in the 16-bit word. */
		*x_mg = (float)(xr >> 4) * LIS_MG_PER_DIGIT;
		*y_mg = (float)(yr >> 4) * LIS_MG_PER_DIGIT;
		*z_mg = (float)(zr >> 4) * LIS_MG_PER_DIGIT;
	} else {
		*x_mg = (float)xr * LSM6_MG_PER_LSB;
		*y_mg = (float)yr * LSM6_MG_PER_LSB;
		*z_mg = (float)zr * LSM6_MG_PER_LSB;
	}
	return true;
}

void accel_read(struct measurement *m)
{
	m->accel_ok = false;

	if (!probed || acc_chip == CHIP_NONE) {
		locate();
		probed = true;
	}
	if (acc_chip == CHIP_NONE) {
		return;
	}

	uint16_t odr_hz = configure();

	if (odr_hz == 0) {
		printk("[ACCEL] config write failed\n");
		power_down();
		return;
	}
	m->accel_sample_rate_hz = odr_hz;

	/* Let the just-(re)enabled ODR and filter chain settle. */
	k_msleep(20);

	const uint32_t period_us = 1000000UL / odr_hz;
	double sum_x = 0.0, sum_y = 0.0, sum_z = 0.0;
	size_t n = 0;

	for (; n < ACCEL_SAMPLE_COUNT; n++) {
		float x, y, z;

		if (!sample_xyz(period_us, &x, &y, &z)) {
			break;
		}
		sum_x += x;
		sum_y += y;
		sum_z += z;
		fft_re[n] = sqrtf(x * x + y * y + z * z); /* |a| for the FFT */
	}
	power_down();

	if (n < ACCEL_SAMPLE_COUNT) {
		/* A short capture is a sensor fault, not a quiet hive. Zero-padding
		 * it under a full-length window weighted the samples that did
		 * arrive by the window's near-zero start and published a valid
		 * looking, far too low reading. */
		printk("[ACCEL] only %u of %u samples; skipping\n", (unsigned)n,
		       (unsigned)ACCEL_SAMPLE_COUNT);
		return;
	}

	/* Mean per-axis acceleration ≈ the static gravity/orientation vector. */
	m->accel_x_mg = (float)(sum_x / (double)n);
	m->accel_y_mg = (float)(sum_y / (double)n);
	m->accel_z_mg = (float)(sum_z / (double)n);
	m->accel_mag_mg = sqrtf(m->accel_x_mg * m->accel_x_mg +
				m->accel_y_mg * m->accel_y_mg +
				m->accel_z_mg * m->accel_z_mg);

	/* Remove DC (gravity + mounting bias) from |a| so the bands reflect AC
	 * vibration only. */
	float sum = 0.0f;

	for (size_t i = 0; i < n; i++) {
		sum += fft_re[i];
	}
	float mean = sum / (float)n;
	float sum_sq = 0.0f, peak_dev = 0.0f;

	for (size_t i = 0; i < n; i++) {
		float ac = fft_re[i] - mean;

		sum_sq += ac * ac;
		float dev = fabsf(ac);

		if (dev > peak_dev) {
			peak_dev = dev;
		}
		fft_re[i] = ac;
		fft_im[i] = 0.0f;
	}

	m->accel_sample_count = (uint16_t)n;
	m->accel_rms_mg = sqrtf(sum_sq / (float)n);
	m->accel_peak_mg = peak_dev;

	hive_fft_hann(fft_re, ACCEL_SAMPLE_COUNT);
	hive_fft_magnitude(fft_re, fft_im, ACCEL_SAMPLE_COUNT);

	const float norm = hive_fft_hann_norm(ACCEL_SAMPLE_COUNT);
	const float fs = (float)odr_hz;

	m->accel_band_swarm_mg = hive_fft_band_amplitude(
		fft_re, ACCEL_SAMPLE_COUNT, fs, ACC_BAND_SWARM_LO,
		ACC_BAND_SWARM_HI, norm, true);
	m->accel_band_fanning_mg = hive_fft_band_amplitude(
		fft_re, ACCEL_SAMPLE_COUNT, fs, ACC_BAND_FANNING_LO,
		ACC_BAND_FANNING_HI, norm, true);
	m->accel_band_activity_mg = hive_fft_band_amplitude(
		fft_re, ACCEL_SAMPLE_COUNT, fs, ACC_BAND_ACTIVITY_LO,
		ACC_BAND_ACTIVITY_HI, norm, true);
	m->accel_ok = true;
}

#else /* !ENABLE_ACCEL */

void accel_read(struct measurement *m)
{
	m->accel_ok = false;
}

#endif /* ENABLE_ACCEL */
```

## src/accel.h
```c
/* accel.h — vibration capture + FFT band analysis.
 *
 * Auto-detects either the XIAO nRF54LM20A Sense on-board LSM6DS3TR-C IMU
 * (0x6A/0x6B) or an external LIS3DH/LIS2DH12 breakout (0x18/0x19) on any
 * enabled I²C bus, then samples ~2.5 s of acceleration at ~400 Hz. It reports
 * both the mean (static/orientation) X/Y/Z and the AC vibration reduced to the
 * shared swarm/fanning/activity bands (the bands HiveScale/HiveHub use).
 */
#pragma once

#include "measurement.h"

/* Capture one vibration snapshot into m (sets m->accel_ok). */
void accel_read(struct measurement *m);
```

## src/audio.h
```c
/* Authenticated, on-request PCM audio service. */
#pragma once

void audio_init(void);
void audio_link_connected(void);
void audio_link_disconnected(void);
```

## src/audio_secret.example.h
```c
/* Copy to audio_secret.h and replace every byte with a securely generated key.
 * The real file is gitignored; an all-zero key deliberately disables START. */
#pragma once
#include <stdint.h>
static const uint8_t hive_audio_psk[32] = {
	0x00, 0x00, 0x00, 0x00, 0x00, 0x00, 0x00, 0x00,
	0x00, 0x00, 0x00, 0x00, 0x00, 0x00, 0x00, 0x00,
	0x00, 0x00, 0x00, 0x00, 0x00, 0x00, 0x00, 0x00,
	0x00, 0x00, 0x00, 0x00, 0x00, 0x00, 0x00, 0x00,
};
```

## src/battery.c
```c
/* battery.c — see battery.h.
 *
 * The XIAO nRF54LM20A carries an nPM1300 PMIC whose charger block measures the
 * cell voltage directly, exposed by Zephyr as a sensor device (compatible
 * `nordic,npm1300-charger`, channel SENSOR_CHAN_GAUGE_VOLTAGE). A simple LiPo
 * curve turns volts into a rough percentage.
 */
#include "battery.h"

#include "hive_config.h"

#include <zephyr/devicetree.h>
#include <zephyr/drivers/sensor.h>
#include <zephyr/sys/printk.h>

#if ENABLE_BATTERY && DT_HAS_COMPAT_STATUS_OKAY(nordic_npm1300_charger)

static const struct device *const charger =
	DEVICE_DT_GET(DT_COMPAT_GET_ANY_STATUS_OKAY(nordic_npm1300_charger));

void battery_read(struct measurement *m)
{
	m->battery_ok = false;

	if (!device_is_ready(charger)) {
		printk("[BATT] nPM1300 charger not ready\n");
		return;
	}

	struct sensor_value val;

	if (sensor_sample_fetch(charger) != 0 ||
	    sensor_channel_get(charger, SENSOR_CHAN_GAUGE_VOLTAGE, &val) != 0) {
		printk("[BATT] fuel-gauge read failed\n");
		return;
	}

	float v = (float)sensor_value_to_double(&val);
	float pct = (v - VBAT_EMPTY_V) / (VBAT_FULL_V - VBAT_EMPTY_V) * 100.0f;

	if (pct < 0.0f) {
		pct = 0.0f;
	}
	if (pct > 100.0f) {
		pct = 100.0f;
	}

	m->battery_v = v;
	m->battery_pct = (uint8_t)(pct + 0.5f);
	m->battery_ok = true;
}

#else /* !ENABLE_BATTERY or no nPM1300 charger node in the devicetree */

void battery_read(struct measurement *m)
{
	m->battery_ok = false;
}

#endif
```

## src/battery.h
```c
/* battery.h — LiPo state from the XIAO's on-board nPM1300 PMIC. */
#pragma once

#include "measurement.h"

/* Read the cell voltage from the nPM1300 charger/fuel-gauge and derive a rough
 * percentage (sets m->battery_ok). A no-op that leaves battery_ok false when
 * the devicetree has no enabled nPM1300 charger node. */
void battery_read(struct measurement *m);
```

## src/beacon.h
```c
/* HiveHub-compatible, connectionless BLE measurement transport. */
#pragma once

#include "measurement.h"

/* Enable Bluetooth. Advertising starts with the first published reading. */
int beacon_init(void);

/* Encode and publish one measurement. The controller repeats it autonomously. */
int beacon_publish(const struct measurement *measurement);

/* Maintain the legacy advertising set around a peripheral connection. */
void beacon_connected(void);
void beacon_disconnected(void);
```
